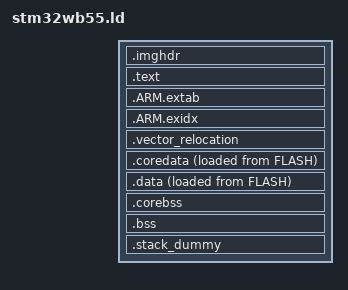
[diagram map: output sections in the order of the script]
/**
*****************************************************************************
**
**  File        : stm32wb55xx_flash_cm4.ld
**
**  Abstract    : System Workbench Minimal System calls file
**
** 		          For more information about which c-functions
**                need which of these lowlevel functions
**                please consult the Newlib libc-manual
**
**  Environment : System Workbench for MCU
**
**  Distribution: The file is distributed “as is,” without any warranty
**                of any kind.
**
*****************************************************************************
**
** <h2><center>&copy; COPYRIGHT(c) 2019 Ac6</center></h2>
**
** Redistribution and use in source and binary forms, with or without modification,
** are permitted provided that the following conditions are met:
**   1. Redistributions of source code must retain the above copyright notice,
**      this list of conditions and the following disclaimer.
**   2. Redistributions in binary form must reproduce the above copyright notice,
**      this list of conditions and the following disclaimer in the documentation
**      and/or other materials provided with the distribution.
**   3. Neither the name of Ac6 nor the names of its contributors
**      may be used to endorse or promote products derived from this software
**      without specific prior written permission.
**
** THIS SOFTWARE IS PROVIDED BY THE COPYRIGHT HOLDERS AND CONTRIBUTORS "AS IS"
** AND ANY EXPRESS OR IMPLIED WARRANTIES, INCLUDING, BUT NOT LIMITED TO, THE
** IMPLIED WARRANTIES OF MERCHANTABILITY AND FITNESS FOR A PARTICULAR PURPOSE ARE
** DISCLAIMED. IN NO EVENT SHALL THE COPYRIGHT HOLDER OR CONTRIBUTORS BE LIABLE
** FOR ANY DIRECT, INDIRECT, INCIDENTAL, SPECIAL, EXEMPLARY, OR CONSEQUENTIAL
** DAMAGES (INCLUDING, BUT NOT LIMITED TO, PROCUREMENT OF SUBSTITUTE GOODS OR
** SERVICES; LOSS OF USE, DATA, OR PROFITS; OR BUSINESS INTERRUPTION) HOWEVER
** CAUSED AND ON ANY THEORY OF LIABILITY, WHETHER IN CONTRACT, STRICT LIABILITY,
** OR TORT (INCLUDING NEGLIGENCE OR OTHERWISE) ARISING IN ANY WAY OUT OF THE USE
** OF THIS SOFTWARE, EVEN IF ADVISED OF THE POSSIBILITY OF SUCH DAMAGE.
**
*****************************************************************************
*/

/* Entry Point */
ENTRY(Reset_Handler)

_estack = ORIGIN(RAM) + LENGTH(RAM);

/* Define output sections */
SECTIONS
{
    /* Reserve space at the start of the image for the header. */
    .imghdr (NOLOAD):
    {
        . = . + _imghdr_size;
    } > FLASH

    .text :
    {
        . = ALIGN(8);
        __isr_vector_start = .;
        KEEP(*(.isr_vector))
        __isr_vector_end = .;
        *(.text*)

        KEEP(*(.init))
        KEEP(*(.fini))

        /* .ctors */
        *crtbegin.o(.ctors)
        *crtbegin?.o(.ctors)
        *(EXCLUDE_FILE(*crtend?.o *crtend.o) .ctors)
        *(SORT(.ctors.*))
        *(.ctors)

        /* .dtors */
        *crtbegin.o(.dtors)
        *crtbegin?.o(.dtors)
        *(EXCLUDE_FILE(*crtend?.o *crtend.o) .dtors)
        *(SORT(.dtors.*))
        *(.dtors)

        *(.rodata*)

        KEEP(*(.eh_frame*))
    } > FLASH

    .ARM.extab :
    {
        *(.ARM.extab* .gnu.linkonce.armextab.*)
    } > FLASH

    __exidx_start = .;
    .ARM.exidx :
    {
        *(.ARM.exidx* .gnu.linkonce.armexidx.*)
    } > FLASH

    __exidx_end = .;

    __etext = .;

    .vector_relocation :
    {
        . = ALIGN(8);
        __vector_tbl_reloc__ = .;
        . = . + (__isr_vector_end - __isr_vector_start);
    } > RAM

    .coredata :
    {
        . = ALIGN(8);
        __coredata_start__ = .;
        *(.data.core)
        __coredata_end__ = .;
    } > RAM AT > FLASH

    __ecoredata = __etext + SIZEOF(.coredata);

    _sidata = LOADADDR(.data);

    .data :
    {
        . = ALIGN(8);
        _sdata = .;
        __data_start__ = _sdata;
        *(vtable)
        *(.data*)

        /* preinit data */
        PROVIDE_HIDDEN (__preinit_array_start = .);
        KEEP(*(.preinit_array))
        PROVIDE_HIDDEN (__preinit_array_end = .);

        . = ALIGN(8);
        /* init data */
        PROVIDE_HIDDEN (__init_array_start = .);
        KEEP(*(SORT(.init_array.*)))
        KEEP(*(.init_array))
        PROVIDE_HIDDEN (__init_array_end = .);


        . = ALIGN(8);
        /* finit data */
        PROVIDE_HIDDEN (__fini_array_start = .);
        KEEP(*(SORT(.fini_array.*)))
        KEEP(*(.fini_array))
        PROVIDE_HIDDEN (__fini_array_end = .);

        KEEP(*(.jcr*))
        . = ALIGN(8);
        /* All data end */
        _edata = .;
        __data_end__ = _edata;

    } > RAM AT > FLASH

    .corebss (NOLOAD):
    {
        . = ALIGN(4);
        __corebss_start__ = .;
        *(.bss.core)
        . = ALIGN(4);
        __corebss_end__ = .;
        *(.corebss*)
        *(.bss.core.nz)
        . = ALIGN(4);
        __ecorebss = .;
    } > RAM

    .bss :
    {
        . = ALIGN(4);
        _sbss = .;
        __bss_start__ = _sbss;
        *(.bss*)
        *(COMMON)
        . = ALIGN(4);
        _ebss = .;
        __bss_end__ = _ebss;
    } > RAM

    . = ALIGN(8);
    __HeapBase = .;
    __HeapLimit = ORIGIN(RAM) + LENGTH(RAM);

    _ram_start = ORIGIN(RAM);

    /* .stack_dummy section doesn't contains any symbols. It is only
     * used for linker to calculate size of stack sections, and assign
     * values to stack symbols later */
    .stack_dummy (COPY):
    {
        *(.stack*)
    } > RAM

    /* Set stack top to end of RAM; stack limit is bottom of stack */
    __StackTop = ORIGIN(RAM) + LENGTH(RAM);
    __StackLimit = __StackTop - SIZEOF(.stack_dummy);
    PROVIDE(__stack = __StackTop);
}
